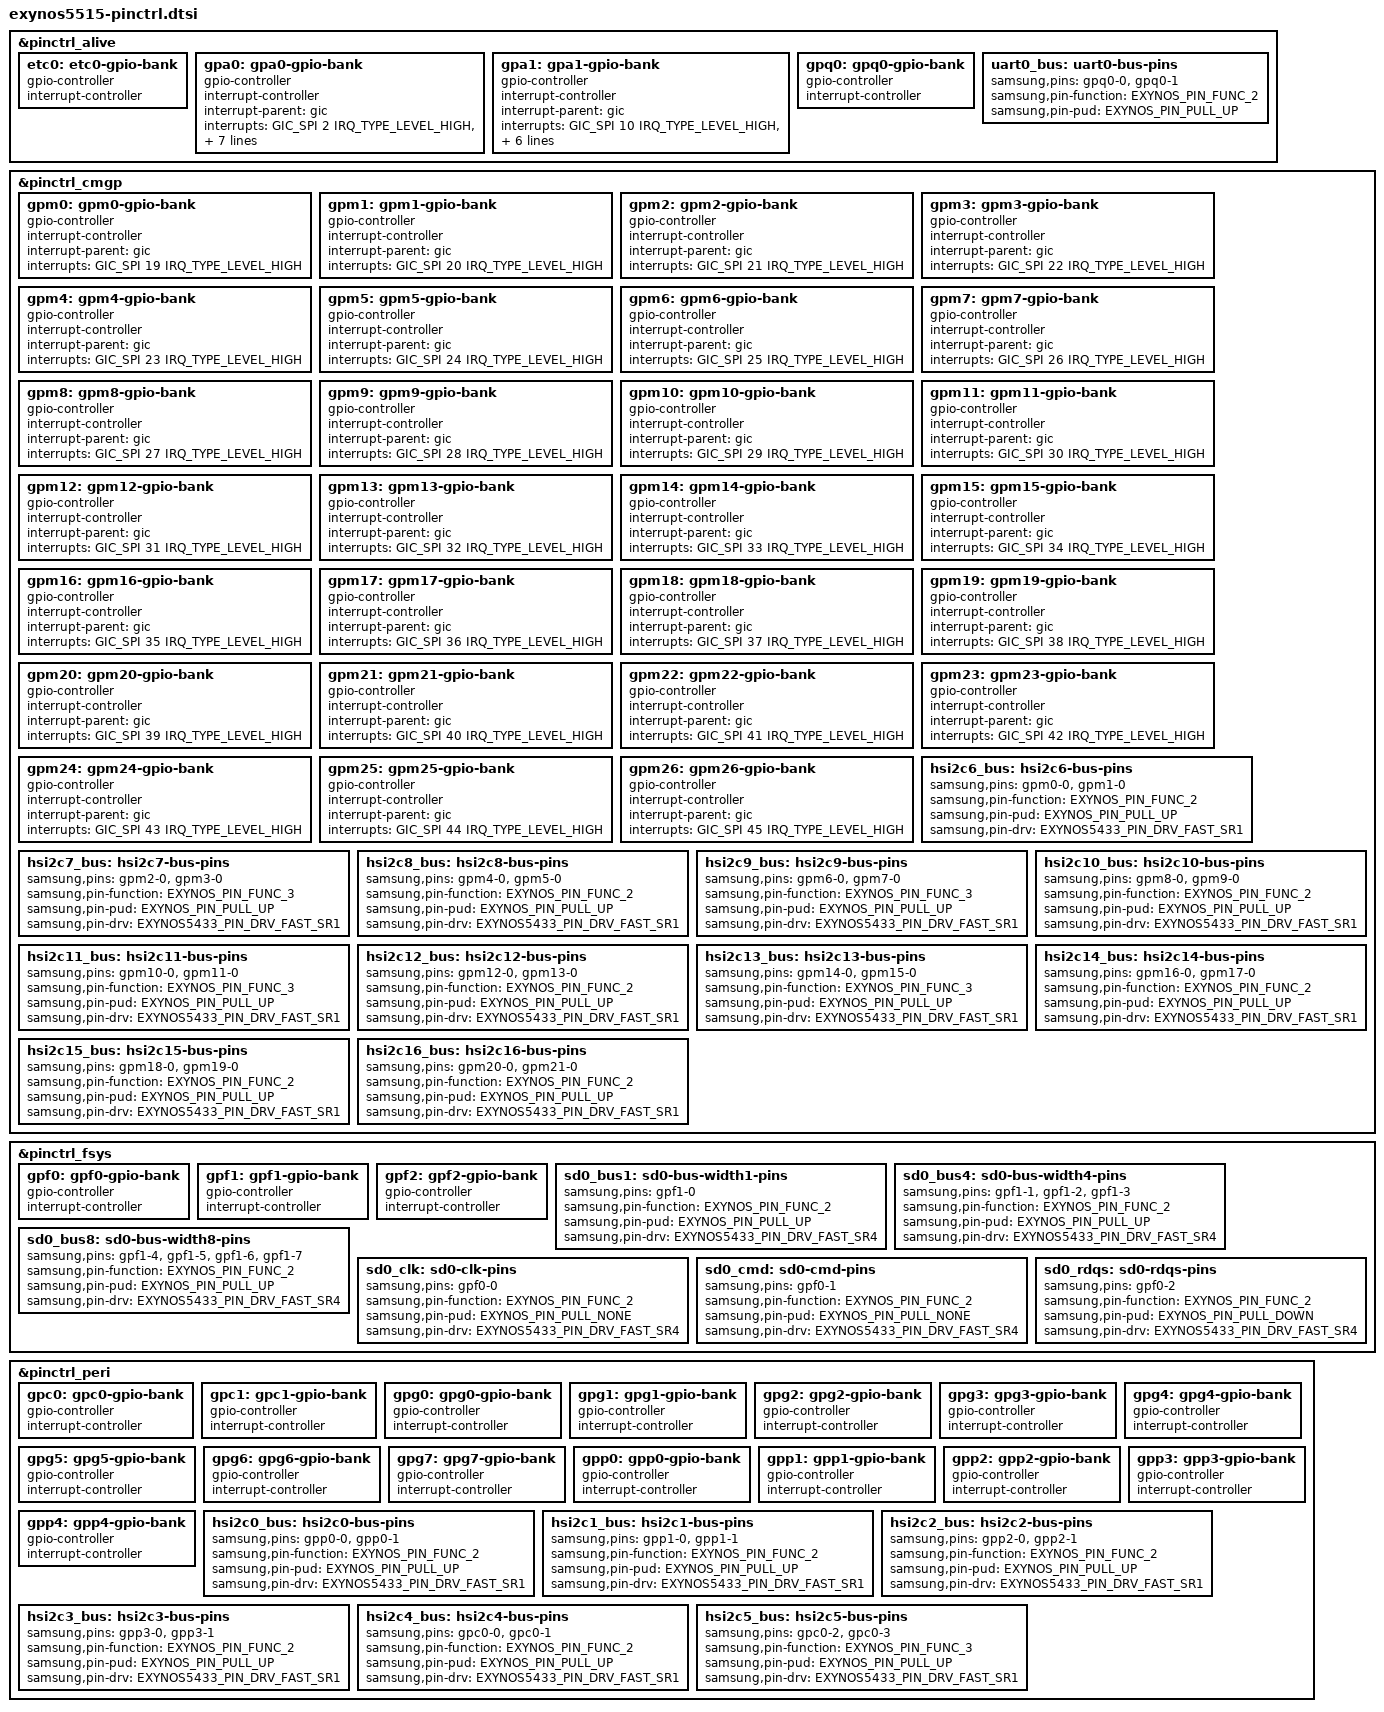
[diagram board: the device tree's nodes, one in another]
// SPDX-License-Identifier: GPL-2.0
/*
 * Samsung Exynos5515 SoC pin-mux and pin-config device tree source
 *
 * Copyright (c) 2017 Samsung Electronics Co., Ltd.
 * Copyright (c) 2026 Aiden Isik <aidenisik+git@member.fsf.org>
 */

#include <dt-bindings/interrupt-controller/arm-gic.h>
#include "exynos-pinctrl.h"

&pinctrl_alive {
	etc0: etc0-gpio-bank {
		gpio-controller;
		#gpio-cells = <2>;

		interrupt-controller;
		#interrupt-cells = <2>;
	};

	gpa0: gpa0-gpio-bank {
		gpio-controller;
		#gpio-cells = <2>;

		interrupt-controller;
		#interrupt-cells = <2>;
		interrupt-parent = <&gic>;
		interrupts = <GIC_SPI 2 IRQ_TYPE_LEVEL_HIGH>,
			     <GIC_SPI 3 IRQ_TYPE_LEVEL_HIGH>,
			     <GIC_SPI 4 IRQ_TYPE_LEVEL_HIGH>,
			     <GIC_SPI 5 IRQ_TYPE_LEVEL_HIGH>,
			     <GIC_SPI 6 IRQ_TYPE_LEVEL_HIGH>,
			     <GIC_SPI 7 IRQ_TYPE_LEVEL_HIGH>,
			     <GIC_SPI 8 IRQ_TYPE_LEVEL_HIGH>,
			     <GIC_SPI 9 IRQ_TYPE_LEVEL_HIGH>;
	};

	gpa1: gpa1-gpio-bank {
		gpio-controller;
		#gpio-cells = <2>;

		interrupt-controller;
		#interrupt-cells = <2>;
		interrupt-parent = <&gic>;
		interrupts = <GIC_SPI 10 IRQ_TYPE_LEVEL_HIGH>,
			     <GIC_SPI 11 IRQ_TYPE_LEVEL_HIGH>,
			     <GIC_SPI 12 IRQ_TYPE_LEVEL_HIGH>,
			     <GIC_SPI 13 IRQ_TYPE_LEVEL_HIGH>,
			     <GIC_SPI 14 IRQ_TYPE_LEVEL_HIGH>,
			     <GIC_SPI 15 IRQ_TYPE_LEVEL_HIGH>,
			     <GIC_SPI 16 IRQ_TYPE_LEVEL_HIGH>;
	};

	gpq0: gpq0-gpio-bank {
		gpio-controller;
		#gpio-cells = <2>;

		interrupt-controller;
		#interrupt-cells = <2>;
	};

	uart0_bus: uart0-bus-pins {
		samsung,pins = "gpq0-0", "gpq0-1";
		samsung,pin-function = <EXYNOS_PIN_FUNC_2>;
		samsung,pin-pud = <EXYNOS_PIN_PULL_UP>;
	};
};

&pinctrl_cmgp {
	gpm0: gpm0-gpio-bank {
		gpio-controller;
		#gpio-cells = <2>;

		interrupt-controller;
		#interrupt-cells = <2>;
		interrupt-parent = <&gic>;
		interrupts = <GIC_SPI 19 IRQ_TYPE_LEVEL_HIGH>;
	};

	gpm1: gpm1-gpio-bank {
		gpio-controller;
		#gpio-cells = <2>;

		interrupt-controller;
		#interrupt-cells = <2>;
		interrupt-parent = <&gic>;
		interrupts = <GIC_SPI 20 IRQ_TYPE_LEVEL_HIGH>;
	};

	gpm2: gpm2-gpio-bank {
		gpio-controller;
		#gpio-cells = <2>;

		interrupt-controller;
		#interrupt-cells = <2>;
		interrupt-parent = <&gic>;
		interrupts = <GIC_SPI 21 IRQ_TYPE_LEVEL_HIGH>;
	};

	gpm3: gpm3-gpio-bank {
		gpio-controller;
		#gpio-cells = <2>;

		interrupt-controller;
		#interrupt-cells = <2>;
		interrupt-parent = <&gic>;
		interrupts = <GIC_SPI 22 IRQ_TYPE_LEVEL_HIGH>;
	};

	gpm4: gpm4-gpio-bank {
		gpio-controller;
		#gpio-cells = <2>;

		interrupt-controller;
		#interrupt-cells = <2>;
		interrupt-parent = <&gic>;
		interrupts = <GIC_SPI 23 IRQ_TYPE_LEVEL_HIGH>;
	};

	gpm5: gpm5-gpio-bank {
		gpio-controller;
		#gpio-cells = <2>;

		interrupt-controller;
		#interrupt-cells = <2>;
		interrupt-parent = <&gic>;
		interrupts = <GIC_SPI 24 IRQ_TYPE_LEVEL_HIGH>;
	};

	gpm6: gpm6-gpio-bank {
		gpio-controller;
		#gpio-cells = <2>;

		interrupt-controller;
		#interrupt-cells = <2>;
		interrupt-parent = <&gic>;
		interrupts = <GIC_SPI 25 IRQ_TYPE_LEVEL_HIGH>;
	};

	gpm7: gpm7-gpio-bank {
		gpio-controller;
		#gpio-cells = <2>;

		interrupt-controller;
		#interrupt-cells = <2>;
		interrupt-parent = <&gic>;
		interrupts = <GIC_SPI 26 IRQ_TYPE_LEVEL_HIGH>;
	};

	gpm8: gpm8-gpio-bank {
		gpio-controller;
		#gpio-cells = <2>;

		interrupt-controller;
		#interrupt-cells = <2>;
		interrupt-parent = <&gic>;
		interrupts = <GIC_SPI 27 IRQ_TYPE_LEVEL_HIGH>;
	};

	gpm9: gpm9-gpio-bank {
		gpio-controller;
		#gpio-cells = <2>;

		interrupt-controller;
		#interrupt-cells = <2>;
		interrupt-parent = <&gic>;
		interrupts = <GIC_SPI 28 IRQ_TYPE_LEVEL_HIGH>;
	};

	gpm10: gpm10-gpio-bank {
		gpio-controller;
		#gpio-cells = <2>;

		interrupt-controller;
		#interrupt-cells = <2>;
		interrupt-parent = <&gic>;
		interrupts = <GIC_SPI 29 IRQ_TYPE_LEVEL_HIGH>;
	};

	gpm11: gpm11-gpio-bank {
		gpio-controller;
		#gpio-cells = <2>;

		interrupt-controller;
		#interrupt-cells = <2>;
		interrupt-parent = <&gic>;
		interrupts = <GIC_SPI 30 IRQ_TYPE_LEVEL_HIGH>;
	};

	gpm12: gpm12-gpio-bank {
		gpio-controller;
		#gpio-cells = <2>;

		interrupt-controller;
		#interrupt-cells = <2>;
		interrupt-parent = <&gic>;
		interrupts = <GIC_SPI 31 IRQ_TYPE_LEVEL_HIGH>;
	};

	gpm13: gpm13-gpio-bank {
		gpio-controller;
		#gpio-cells = <2>;

		interrupt-controller;
		#interrupt-cells = <2>;
		interrupt-parent = <&gic>;
		interrupts = <GIC_SPI 32 IRQ_TYPE_LEVEL_HIGH>;
	};

	gpm14: gpm14-gpio-bank {
		gpio-controller;
		#gpio-cells = <2>;

		interrupt-controller;
		#interrupt-cells = <2>;
		interrupt-parent = <&gic>;
		interrupts = <GIC_SPI 33 IRQ_TYPE_LEVEL_HIGH>;
	};

	gpm15: gpm15-gpio-bank {
		gpio-controller;
		#gpio-cells = <2>;

		interrupt-controller;
		#interrupt-cells = <2>;
		interrupt-parent = <&gic>;
		interrupts = <GIC_SPI 34 IRQ_TYPE_LEVEL_HIGH>;
	};

	gpm16: gpm16-gpio-bank {
		gpio-controller;
		#gpio-cells = <2>;

		interrupt-controller;
		#interrupt-cells = <2>;
		interrupt-parent = <&gic>;
		interrupts = <GIC_SPI 35 IRQ_TYPE_LEVEL_HIGH>;
	};

	gpm17: gpm17-gpio-bank {
		gpio-controller;
		#gpio-cells = <2>;

		interrupt-controller;
		#interrupt-cells = <2>;
		interrupt-parent = <&gic>;
		interrupts = <GIC_SPI 36 IRQ_TYPE_LEVEL_HIGH>;
	};

	gpm18: gpm18-gpio-bank {
		gpio-controller;
		#gpio-cells = <2>;

		interrupt-controller;
		#interrupt-cells = <2>;
		interrupt-parent = <&gic>;
		interrupts = <GIC_SPI 37 IRQ_TYPE_LEVEL_HIGH>;
	};

	gpm19: gpm19-gpio-bank {
		gpio-controller;
		#gpio-cells = <2>;

		interrupt-controller;
		#interrupt-cells = <2>;
		interrupt-parent = <&gic>;
		interrupts = <GIC_SPI 38 IRQ_TYPE_LEVEL_HIGH>;
	};

	gpm20: gpm20-gpio-bank {
		gpio-controller;
		#gpio-cells = <2>;

		interrupt-controller;
		#interrupt-cells = <2>;
		interrupt-parent = <&gic>;
		interrupts = <GIC_SPI 39 IRQ_TYPE_LEVEL_HIGH>;
	};

	gpm21: gpm21-gpio-bank {
		gpio-controller;
		#gpio-cells = <2>;

		interrupt-controller;
		#interrupt-cells = <2>;
		interrupt-parent = <&gic>;
		interrupts = <GIC_SPI 40 IRQ_TYPE_LEVEL_HIGH>;
	};

	gpm22: gpm22-gpio-bank {
		gpio-controller;
		#gpio-cells = <2>;

		interrupt-controller;
		#interrupt-cells = <2>;
		interrupt-parent = <&gic>;
		interrupts = <GIC_SPI 41 IRQ_TYPE_LEVEL_HIGH>;
	};

	gpm23: gpm23-gpio-bank {
		gpio-controller;
		#gpio-cells = <2>;

		interrupt-controller;
		#interrupt-cells = <2>;
		interrupt-parent = <&gic>;
		interrupts = <GIC_SPI 42 IRQ_TYPE_LEVEL_HIGH>;
	};

	gpm24: gpm24-gpio-bank {
		gpio-controller;
		#gpio-cells = <2>;

		interrupt-controller;
		#interrupt-cells = <2>;
		interrupt-parent = <&gic>;
		interrupts = <GIC_SPI 43 IRQ_TYPE_LEVEL_HIGH>;
	};

	gpm25: gpm25-gpio-bank {
		gpio-controller;
		#gpio-cells = <2>;

		interrupt-controller;
		#interrupt-cells = <2>;
		interrupt-parent = <&gic>;
		interrupts = <GIC_SPI 44 IRQ_TYPE_LEVEL_HIGH>;
	};

	gpm26: gpm26-gpio-bank {
		gpio-controller;
		#gpio-cells = <2>;

		interrupt-controller;
		#interrupt-cells = <2>;
		interrupt-parent = <&gic>;
		interrupts = <GIC_SPI 45 IRQ_TYPE_LEVEL_HIGH>;
	};

	hsi2c6_bus: hsi2c6-bus-pins {
		samsung,pins = "gpm0-0", "gpm1-0";
		samsung,pin-function = <EXYNOS_PIN_FUNC_2>;
		samsung,pin-pud = <EXYNOS_PIN_PULL_UP>;
		samsung,pin-drv = <EXYNOS5433_PIN_DRV_FAST_SR1>;
	};

	hsi2c7_bus: hsi2c7-bus-pins {
		samsung,pins = "gpm2-0", "gpm3-0";
		samsung,pin-function = <EXYNOS_PIN_FUNC_3>;
		samsung,pin-pud = <EXYNOS_PIN_PULL_UP>;
		samsung,pin-drv = <EXYNOS5433_PIN_DRV_FAST_SR1>;
	};

	hsi2c8_bus: hsi2c8-bus-pins {
		samsung,pins = "gpm4-0", "gpm5-0";
		samsung,pin-function = <EXYNOS_PIN_FUNC_2>;
		samsung,pin-pud = <EXYNOS_PIN_PULL_UP>;
		samsung,pin-drv = <EXYNOS5433_PIN_DRV_FAST_SR1>;
	};

	hsi2c9_bus: hsi2c9-bus-pins {
		samsung,pins = "gpm6-0", "gpm7-0";
		samsung,pin-function = <EXYNOS_PIN_FUNC_3>;
		samsung,pin-pud = <EXYNOS_PIN_PULL_UP>;
		samsung,pin-drv = <EXYNOS5433_PIN_DRV_FAST_SR1>;
	};

	hsi2c10_bus: hsi2c10-bus-pins {
		samsung,pins = "gpm8-0", "gpm9-0";
		samsung,pin-function = <EXYNOS_PIN_FUNC_2>;
		samsung,pin-pud = <EXYNOS_PIN_PULL_UP>;
		samsung,pin-drv = <EXYNOS5433_PIN_DRV_FAST_SR1>;
	};

	hsi2c11_bus: hsi2c11-bus-pins {
		samsung,pins = "gpm10-0", "gpm11-0";
		samsung,pin-function = <EXYNOS_PIN_FUNC_3>;
		samsung,pin-pud = <EXYNOS_PIN_PULL_UP>;
		samsung,pin-drv = <EXYNOS5433_PIN_DRV_FAST_SR1>;
	};

	hsi2c12_bus: hsi2c12-bus-pins {
		samsung,pins = "gpm12-0", "gpm13-0";
		samsung,pin-function = <EXYNOS_PIN_FUNC_2>;
		samsung,pin-pud = <EXYNOS_PIN_PULL_UP>;
		samsung,pin-drv = <EXYNOS5433_PIN_DRV_FAST_SR1>;
	};

	hsi2c13_bus: hsi2c13-bus-pins {
		samsung,pins = "gpm14-0", "gpm15-0";
		samsung,pin-function = <EXYNOS_PIN_FUNC_3>;
		samsung,pin-pud = <EXYNOS_PIN_PULL_UP>;
		samsung,pin-drv = <EXYNOS5433_PIN_DRV_FAST_SR1>;
	};

	hsi2c14_bus: hsi2c14-bus-pins {
		samsung,pins = "gpm16-0", "gpm17-0";
		samsung,pin-function = <EXYNOS_PIN_FUNC_2>;
		samsung,pin-pud = <EXYNOS_PIN_PULL_UP>;
		samsung,pin-drv = <EXYNOS5433_PIN_DRV_FAST_SR1>;
	};

	hsi2c15_bus: hsi2c15-bus-pins {
		samsung,pins = "gpm18-0", "gpm19-0";
		samsung,pin-function = <EXYNOS_PIN_FUNC_2>;
		samsung,pin-pud = <EXYNOS_PIN_PULL_UP>;
		samsung,pin-drv = <EXYNOS5433_PIN_DRV_FAST_SR1>;
	};

	hsi2c16_bus: hsi2c16-bus-pins {
		samsung,pins = "gpm20-0", "gpm21-0";
		samsung,pin-function = <EXYNOS_PIN_FUNC_2>;
		samsung,pin-pud = <EXYNOS_PIN_PULL_UP>;
		samsung,pin-drv = <EXYNOS5433_PIN_DRV_FAST_SR1>;
	};
};

&pinctrl_fsys {
	gpf0: gpf0-gpio-bank {
		gpio-controller;
		#gpio-cells = <2>;

		interrupt-controller;
		#interrupt-cells = <2>;
	};

	gpf1: gpf1-gpio-bank {
		gpio-controller;
		#gpio-cells = <2>;

		interrupt-controller;
		#interrupt-cells = <2>;
	};

	gpf2: gpf2-gpio-bank {
		gpio-controller;
		#gpio-cells = <2>;

		interrupt-controller;
		#interrupt-cells = <2>;
	};

	sd0_bus1: sd0-bus-width1-pins {
		samsung,pins = "gpf1-0";
		samsung,pin-function = <EXYNOS_PIN_FUNC_2>;
		samsung,pin-pud = <EXYNOS_PIN_PULL_UP>;
		samsung,pin-drv = <EXYNOS5433_PIN_DRV_FAST_SR4>;
	};

	sd0_bus4: sd0-bus-width4-pins {
		samsung,pins = "gpf1-1", "gpf1-2", "gpf1-3";
		samsung,pin-function = <EXYNOS_PIN_FUNC_2>;
		samsung,pin-pud = <EXYNOS_PIN_PULL_UP>;
		samsung,pin-drv = <EXYNOS5433_PIN_DRV_FAST_SR4>;
	};

	sd0_bus8: sd0-bus-width8-pins {
		samsung,pins = "gpf1-4", "gpf1-5", "gpf1-6", "gpf1-7";
		samsung,pin-function = <EXYNOS_PIN_FUNC_2>;
		samsung,pin-pud = <EXYNOS_PIN_PULL_UP>;
		samsung,pin-drv = <EXYNOS5433_PIN_DRV_FAST_SR4>;
	};

	sd0_clk: sd0-clk-pins {
		samsung,pins = "gpf0-0";
		samsung,pin-function = <EXYNOS_PIN_FUNC_2>;
		samsung,pin-pud = <EXYNOS_PIN_PULL_NONE>;
		samsung,pin-drv = <EXYNOS5433_PIN_DRV_FAST_SR4>;
	};

	sd0_cmd: sd0-cmd-pins {
		samsung,pins = "gpf0-1";
		samsung,pin-function = <EXYNOS_PIN_FUNC_2>;
		samsung,pin-pud = <EXYNOS_PIN_PULL_NONE>;
		samsung,pin-drv = <EXYNOS5433_PIN_DRV_FAST_SR4>;
	};

	sd0_rdqs: sd0-rdqs-pins {
		samsung,pins = "gpf0-2";
		samsung,pin-function = <EXYNOS_PIN_FUNC_2>;
		samsung,pin-pud = <EXYNOS_PIN_PULL_DOWN>;
		samsung,pin-drv = <EXYNOS5433_PIN_DRV_FAST_SR4>;
	};
};

&pinctrl_peri {
	gpc0: gpc0-gpio-bank {
		gpio-controller;
		#gpio-cells = <2>;

		interrupt-controller;
		#interrupt-cells = <2>;
	};

	gpc1: gpc1-gpio-bank {
		gpio-controller;
		#gpio-cells = <2>;

		interrupt-controller;
		#interrupt-cells = <2>;
	};

	gpg0: gpg0-gpio-bank {
		gpio-controller;
		#gpio-cells = <2>;

		interrupt-controller;
		#interrupt-cells = <2>;
	};

	gpg1: gpg1-gpio-bank {
		gpio-controller;
		#gpio-cells = <2>;

		interrupt-controller;
		#interrupt-cells = <2>;
	};

	gpg2: gpg2-gpio-bank {
		gpio-controller;
		#gpio-cells = <2>;

		interrupt-controller;
		#interrupt-cells = <2>;
	};

	gpg3: gpg3-gpio-bank {
		gpio-controller;
		#gpio-cells = <2>;

		interrupt-controller;
		#interrupt-cells = <2>;
	};

	gpg4: gpg4-gpio-bank {
		gpio-controller;
		#gpio-cells = <2>;

		interrupt-controller;
		#interrupt-cells = <2>;
	};

	gpg5: gpg5-gpio-bank {
		gpio-controller;
		#gpio-cells = <2>;

		interrupt-controller;
		#interrupt-cells = <2>;
	};

	gpg6: gpg6-gpio-bank {
		gpio-controller;
		#gpio-cells = <2>;

		interrupt-controller;
		#interrupt-cells = <2>;
	};

	gpg7: gpg7-gpio-bank {
		gpio-controller;
		#gpio-cells = <2>;

		interrupt-controller;
		#interrupt-cells = <2>;
	};

	gpp0: gpp0-gpio-bank {
		gpio-controller;
		#gpio-cells = <2>;

		interrupt-controller;
		#interrupt-cells = <2>;
	};

	gpp1: gpp1-gpio-bank {
		gpio-controller;
		#gpio-cells = <2>;

		interrupt-controller;
		#interrupt-cells = <2>;
	};

	gpp2: gpp2-gpio-bank {
		gpio-controller;
		#gpio-cells = <2>;

		interrupt-controller;
		#interrupt-cells = <2>;
	};

	gpp3: gpp3-gpio-bank {
		gpio-controller;
		#gpio-cells = <2>;

		interrupt-controller;
		#interrupt-cells = <2>;
	};

	gpp4: gpp4-gpio-bank {
		gpio-controller;
		#gpio-cells = <2>;

		interrupt-controller;
		#interrupt-cells = <2>;
	};

	hsi2c0_bus: hsi2c0-bus-pins {
		samsung,pins = "gpp0-0", "gpp0-1";
		samsung,pin-function = <EXYNOS_PIN_FUNC_2>;
		samsung,pin-pud = <EXYNOS_PIN_PULL_UP>;
		samsung,pin-drv = <EXYNOS5433_PIN_DRV_FAST_SR1>;
	};

	hsi2c1_bus: hsi2c1-bus-pins {
		samsung,pins = "gpp1-0", "gpp1-1";
		samsung,pin-function = <EXYNOS_PIN_FUNC_2>;
		samsung,pin-pud = <EXYNOS_PIN_PULL_UP>;
		samsung,pin-drv = <EXYNOS5433_PIN_DRV_FAST_SR1>;
	};

	hsi2c2_bus: hsi2c2-bus-pins {
		samsung,pins = "gpp2-0", "gpp2-1";
		samsung,pin-function = <EXYNOS_PIN_FUNC_2>;
		samsung,pin-pud = <EXYNOS_PIN_PULL_UP>;
		samsung,pin-drv = <EXYNOS5433_PIN_DRV_FAST_SR1>;
	};

	hsi2c3_bus: hsi2c3-bus-pins {
		samsung,pins = "gpp3-0", "gpp3-1";
		samsung,pin-function = <EXYNOS_PIN_FUNC_2>;
		samsung,pin-pud = <EXYNOS_PIN_PULL_UP>;
		samsung,pin-drv = <EXYNOS5433_PIN_DRV_FAST_SR1>;
	};

	hsi2c4_bus: hsi2c4-bus-pins {
		samsung,pins = "gpc0-0", "gpc0-1";
		samsung,pin-function = <EXYNOS_PIN_FUNC_2>;
		samsung,pin-pud = <EXYNOS_PIN_PULL_UP>;
		samsung,pin-drv = <EXYNOS5433_PIN_DRV_FAST_SR1>;
	};

	hsi2c5_bus: hsi2c5-bus-pins {
		samsung,pins = "gpc0-2", "gpc0-3";
		samsung,pin-function = <EXYNOS_PIN_FUNC_3>;
		samsung,pin-pud = <EXYNOS_PIN_PULL_UP>;
		samsung,pin-drv = <EXYNOS5433_PIN_DRV_FAST_SR1>;
	};
};
